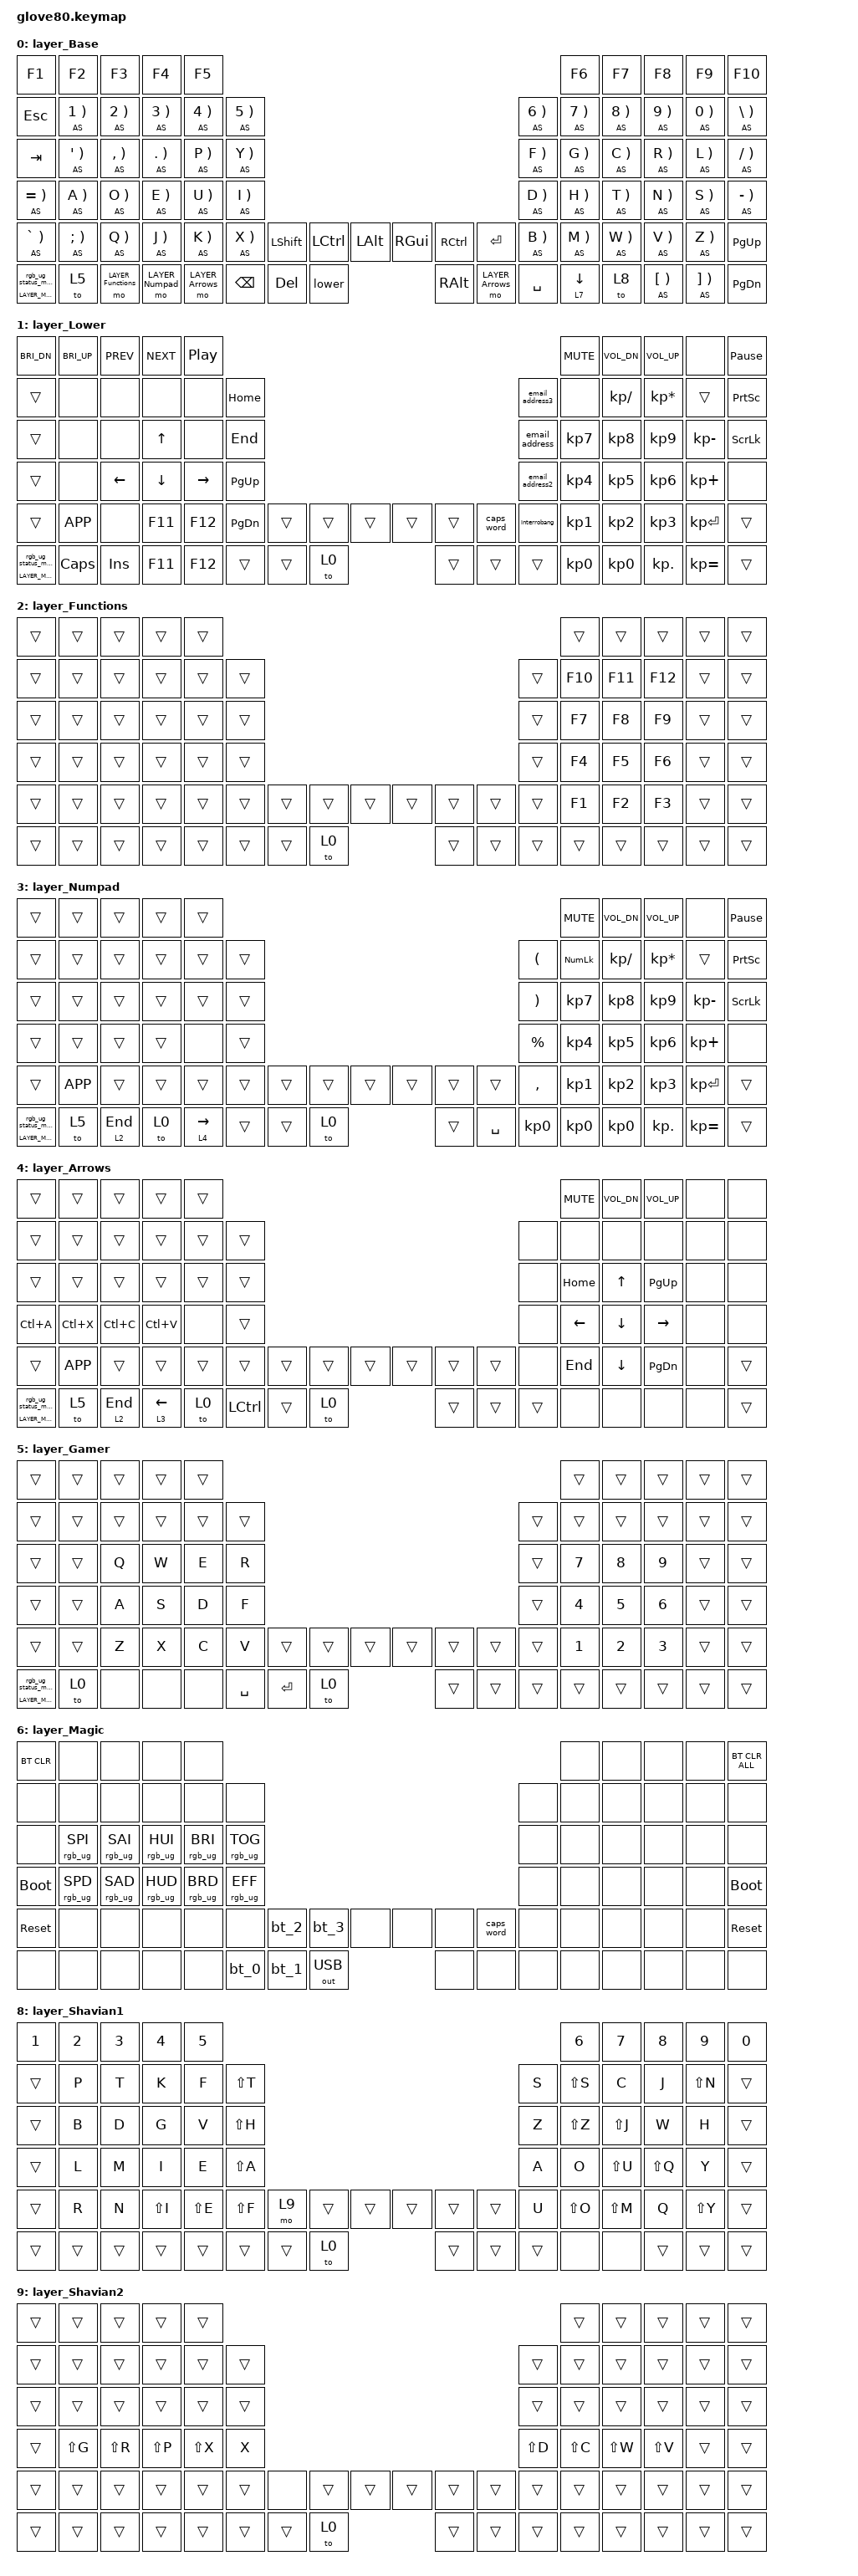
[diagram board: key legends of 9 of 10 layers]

/*
 * Copyright (c) 2020 The ZMK Contributors
 * Copyright (c) 2023 Innaworks Development Limited, trading as MoErgo
 *
 * SPDX-License-Identifier: MIT
 */


/* THIS FILE WAS GENERATED BY GLOVE80 LAYOUT EDITOR
 *
 * This file was generated automatically. You may or may not want to
 * edit it directly.
 */

#include <behaviors.dtsi>
/* Include all behaviour includes needed */
#include <dt-bindings/zmk/outputs.h>
#include <dt-bindings/zmk/keys.h>
#include <dt-bindings/zmk/bt.h>
#include <dt-bindings/zmk/rgb.h>
#include <dt-bindings/zmk/rgb_colors.h>

/* Automatically generated layer name #define */
#define LAYER_Base 0
#define LAYER_Lower 1
#define LAYER_Functions 2
#define LAYER_Numpad 3
#define LAYER_Arrows 4
#define LAYER_Gamer 5
#define LAYER_Magic 6
#define LAYER_OBS 7
#define LAYER_Shavian1 8
#define LAYER_Shavian2 9

/* To deal with the situation where there is no Lower layer, to keep &lower happy */
#ifndef LAYER_Lower
#define LAYER_Lower 0
#endif 

/* Custom Device-tree */
// KEY_REPEATING_TERM defines how much time you have left (milliseconds)
// after tapping a key to hold it again in order to make it auto-repeat.
#define KEY_REPEATING_TERM 800 // "tap then hold" for key auto-repeat

// TAPPING_TERM defines how long you need to hold (milliseconds)
// mod keys in order to send their modifiers to the computer
// (i.e. "register" them) for mod-click mouse usage (e.g. Ctrl-Click).
#define TAPPING_TERM 370 // TAPPING_TERM + ALLOW_CROSSOVER_AFTER
    
// AUTO_SHIFT_TERM defines how long you need to hold (milliseconds)
// a key in order to send its shifted version to the computer.
#define AUTO_SHIFT_TERM 300 // AUTO_SHIFT_TERM + ALLOW_CROSSOVER_AFTER

&mt {
    flavor = "hold-preferred";
    tapping-term-ms = <TAPPING_TERM>;
    quick-tap-ms = <KEY_REPEATING_TERM>;
};

&lt {
    flavor = "hold-preferred";
    tapping-term-ms = <TAPPING_TERM>;
    quick-tap-ms = <KEY_REPEATING_TERM>;
};


/ {
    underglow-layer {
        compatible  = "zmk,underglow-layer";

        lower {
            bindings = <
                ______ ______ ______ ______ ______                                                          ______ ______ ______ ______ ______
                ______ ______ ______ ______ ______ ______                                              BLUE ______ ______ ______ ______   PINK
                ______ ______ ______ ______ ______ ______                                              BLUE ______ ______ ______ ______   PINK
                ______ ______ ______ ______ ______ ______                                              BLUE ______ ______ ______ ______   PINK
                ______   PINK ______ YELLOW YELLOW ______ ______ ______ ______ ______  ______   PINK YELLOW ______ ______ ______ ______ ______
                ______   PINK ______ YELLOW YELLOW        ______  GREEN ______  ______ ______ ______        ______ ______ ______ ______ ______
                >;
            layer-id = <LAYER_Lower>;
        };
        arrows {
            bindings = <
                ______ ______ ______ ______ ______                                                          ______ ______ ______ ______ ______
                ______ ______ ______ ______ ______ ______                                            ______ ______ ______ ______ ______ ______
                ______ ______ ______ ______ ______ ______                                            ______   BLUE   BLUE   BLUE ______ ______
                  TEAL   BLUE   BLUE   BLUE ______ ______                                            ______   BLUE   BLUE   BLUE ______ ______
                ______ ______ ______ ______ ______ ______ ______ ______ ______  ______ ______ ______ ______   BLUE   BLUE   BLUE ______ ______
                ______ ______ ______ ______ ______          BLUE ______ ______  ______ ______ ______        ______ ______ ______ ______ ______
                >;
            layer-id = <LAYER_Arrows>;
        };
        numpad {
            bindings = <
                ______ ______ ______ ______ ______                                                          ______ ______ ______ ______ ______
                ______ ______ ______ ______ ______ ______                                            ______  GREEN  GREEN  GREEN ______ ______
                ______ ______ ______ ______ ______ ______                                            ______   TEAL   TEAL   TEAL  GREEN ______
                ______ ______ ______ ______ ______ ______                                              TEAL   TEAL   TEAL   TEAL  GREEN ______
                ______ ______ ______ ______ ______ ______ ______ ______ ______  ______ ______ ______   TEAL   TEAL   TEAL   TEAL  GREEN ______
                ______ ______ ______ ______ ______        ______ ______ ______  ______ ______   TEAL          TEAL   TEAL   TEAL  GREEN ______
                >;
            layer-id = <LAYER_Numpad>;
        };
        functions {
            bindings = <
                ______ ______ ______ ______ ______                                                          ______ ______ ______ ______ ______
                ______ ______ ______ ______ ______ ______                                            ______ YELLOW YELLOW YELLOW ______ ______
                ______ ______ ______ ______ ______ ______                                            ______ YELLOW YELLOW YELLOW ______ ______
                ______ ______ ______ ______ ______ ______                                            ______ YELLOW YELLOW YELLOW ______ ______
                ______ ______ ______ ______ ______ ______ ______ ______ ______  ______ ______ ______ ______ YELLOW YELLOW YELLOW ______ ______
                ______ ______ ______ ______ ______        ______ ______ ______  ______ ______ ______        ______ ______ ______ ______ ______
                >;
            layer-id = <LAYER_Functions>;
        };
        shavian1 {
            bindings = <
                  GOLD   GOLD   GOLD   GOLD   GOLD                                                            GOLD   GOLD   GOLD   GOLD   GOLD
                ______   GOLD   GOLD   GOLD   GOLD   GOLD                                              GOLD   GOLD   GOLD   GOLD   GOLD   GOLD
                ______   GOLD   GOLD   GOLD   GOLD   GOLD                                              GOLD   GOLD   GOLD   GOLD   GOLD ______
                ______   GOLD   GOLD   GOLD   GOLD   GOLD                                              GOLD   GOLD   GOLD   GOLD   GOLD ______
                ______   GOLD   GOLD   GOLD   GOLD   GOLD   GOLD ______ ______  ______ ______ ______   GOLD   GOLD   GOLD   GOLD   GOLD ______
                ______ ______ ______ ______ ______        ______ ______    RED  ______ ______ ______        ______ ______ ______ ______ ______
                >;
            layer-id = <LAYER_Shavian1>;
        };
        shavian2 {
            bindings = <
                ______ ______ ______ ______ ______                                                          ______ ______ ______ ______ ______
                ______ ______ ______ ______ ______ ______                                            ______ ______ ______ ______ ______ ______
                ______ ______ ______ ______ ______ ______                                            ______ ______ ______ ______ ______ ______
                ______   GOLD   GOLD   GOLD   GOLD   GOLD                                              GOLD   GOLD   GOLD   GOLD   GOLD ______
                ______ ______ ______ ______ ______ ______ ______ ______ ______  ______ ______ ______ ______ ______ ______ ______ ______ ______
                ______ ______ ______ ______ ______        ______ ______    RED  ______ ______ ______        ______ ______ ______ ______ ______
                >;
            layer-id = <LAYER_Shavian2>;
        };
        obs {
            bindings = <
                ______ ______ ______ ______ ______                                                          ______ ______ ______ ______ ______
                ______ ______ ______    RED ______  GREEN                                            ______ ______ ______ ______ ______ ______
                ______ ______ ORANGE   BLUE ______ ORANGE                                            ______ ______ ______ ______ ______ ______
                ______   GOLD   BLUE  GREEN   BLUE  GREEN                                            ______ ______ ______ ______ ______ ______
                ______ PURPLE   PINK   TEAL ______  GREEN ______ ______ ______  ______ ______ ______ ______ ______ ______ ______ ______ ______
                ______ ______  WHITE   TEAL ______        ______ ______ ______  ______ ______ ______        ______ ______ ______ ______ ______
                >;
            layer-id = <LAYER_OBS>;
        };
        gamer {
            bindings = <
                ______ ______ ______ ______ ______                                                          ______ ______ ______ ______ ______
                ______ ______ ______ ______ ______ ______                                            ______ ______ ______ ______ ______ ______
                ______ ______    RED    RED    RED ______                                            ______    RED    RED    RED ______ ______
                ______ ______    RED    RED    RED ______                                            ______    RED    RED    RED ______ ______
                ______ ______    RED    RED    RED ______ ______ ______ ______  ______ ______ ______ ______    RED    RED    RED ______ ______
                ______ ______ ______ ______ ______           RED    RED ______  ______ ______ ______        ______ ______ ______ ______ ______
                >;
            layer-id = <LAYER_Gamer>;
        };


    };
};


/* Glove80 system behavior & macros */
/ {
    behaviors {
        // For the "layer" key, it'd nice to be able to use it as either a shift or a toggle.
        // Configure it as a tap dance, so the first tap (or hold) is a &mo and the second tap is a &to
        lower: lower {
            compatible = "zmk,behavior-tap-dance";
            label = "LAYER_TAP_DANCE";
            #binding-cells = <0>;
            tapping-term-ms = <200>;
            bindings = <&mo LAYER_Lower>, <&to LAYER_Lower>;
        };
    };
};

/ {
    macros {
        rgb_ug_status_macro: rgb_ug_status_macro {
            label = "RGB_UG_STATUS";
            compatible = "zmk,behavior-macro";
            #binding-cells = <0>;
            bindings
                = <&rgb_ug RGB_STATUS>;
        };
    };
};


/ {
#ifdef BT_DISC_CMD
    behaviors {
        bt_0: bt_0 {
            compatible = "zmk,behavior-tap-dance";
            label = "BT_0";
            #binding-cells = <0>;
            tapping-term-ms = <200>;
            bindings = <&bt_select_0>, <&bt BT_DISC 0>;
        };
        bt_1: bt_1 {
            compatible = "zmk,behavior-tap-dance";
            label = "BT_1";
            #binding-cells = <0>;
            tapping-term-ms = <200>;
            bindings = <&bt_select_1>, <&bt BT_DISC 1>;
        };
        bt_2: bt_2 {
            compatible = "zmk,behavior-tap-dance";
            label = "BT_2";
            #binding-cells = <0>;
            tapping-term-ms = <200>;
            bindings = <&bt_select_2>, <&bt BT_DISC 2>;
        };
        bt_3: bt_3 {
            compatible = "zmk,behavior-tap-dance";
            label = "BT_3";
            #binding-cells = <0>;
            tapping-term-ms = <200>;
            bindings = <&bt_select_3>, <&bt BT_DISC 3>;
        };
    };
    macros {
        bt_select_0: bt_select_0 {
            label = "BT_SELECT_0";
            compatible = "zmk,behavior-macro";
            #binding-cells = <0>;
            bindings
                = <&out OUT_BLE>,
                  <&bt BT_SEL 0>;
        };
        bt_select_1: bt_select_1 {
            label = "BT_SELECT_1";
            compatible = "zmk,behavior-macro";
            #binding-cells = <0>;
            bindings
                = <&out OUT_BLE>,
                  <&bt BT_SEL 1>;
        };
        bt_select_2: bt_select_2 {
            label = "BT_SELECT_2";
            compatible = "zmk,behavior-macro";
            #binding-cells = <0>;
            bindings
                = <&out OUT_BLE>,
                  <&bt BT_SEL 2>;
        };
        bt_select_3: bt_select_3 {
            label = "BT_SELECT_3";
            compatible = "zmk,behavior-macro";
            #binding-cells = <0>;
            bindings
                = <&out OUT_BLE>,
                  <&bt BT_SEL 3>;
        };
    };
#else
    macros {
        bt_0: bt_0 {
            label = "BT_0";
            compatible = "zmk,behavior-macro";
            #binding-cells = <0>;
            bindings
                = <&out OUT_BLE>,
                  <&bt BT_SEL 0>;
        };
        bt_1: bt_1 {
            label = "BT_1";
            compatible = "zmk,behavior-macro";
            #binding-cells = <0>;
            bindings
                = <&out OUT_BLE>,
                  <&bt BT_SEL 1>;
        };
        bt_2: bt_2 {
            label = "BT_2";
            compatible = "zmk,behavior-macro";
            #binding-cells = <0>;
            bindings
                = <&out OUT_BLE>,
                  <&bt BT_SEL 2>;
        };
        bt_3: bt_3 {
            label = "BT_3";
            compatible = "zmk,behavior-macro";
            #binding-cells = <0>;
            bindings
                = <&out OUT_BLE>,
                  <&bt BT_SEL 3>;
        };
    };
#endif
};

/ {
    behaviors {
        magic: magic {
            compatible = "zmk,behavior-hold-tap";
            label = "MAGIC_HOLD_TAP";
            #binding-cells = <2>;
            flavor = "tap-preferred";
            tapping-term-ms = <200>;
            bindings = <&mo>, <&rgb_ug_status_macro>;
        };
    };
};

/* #define for key positions */
#define POS_LH_T1 52
#define POS_LH_T2 53
#define POS_LH_T3 54
#define POS_LH_T4 69
#define POS_LH_T5 70
#define POS_LH_T6 71
#define POS_LH_C1R2 15
#define POS_LH_C1R3 27
#define POS_LH_C1R4 39
#define POS_LH_C1R5 51
#define POS_LH_C2R1 4
#define POS_LH_C2R2 14
#define POS_LH_C2R3 26
#define POS_LH_C2R4 38
#define POS_LH_C2R5 50
#define POS_LH_C2R6 68
#define POS_LH_C3R1 3
#define POS_LH_C3R2 13
#define POS_LH_C3R3 25
#define POS_LH_C3R4 37
#define POS_LH_C3R5 49
#define POS_LH_C3R6 67
#define POS_LH_C4R1 2
#define POS_LH_C4R2 12
#define POS_LH_C4R3 24
#define POS_LH_C4R4 36
#define POS_LH_C4R5 48
#define POS_LH_C4R6 66
#define POS_LH_C5R1 1
#define POS_LH_C5R2 11
#define POS_LH_C5R3 23
#define POS_LH_C5R4 35
#define POS_LH_C5R5 47
#define POS_LH_C5R6 65
#define POS_LH_C6R1 0
#define POS_LH_C6R2 10
#define POS_LH_C6R3 22
#define POS_LH_C6R4 34
#define POS_LH_C6R5 46
#define POS_LH_C6R6 64
#define POS_RH_T1 57
#define POS_RH_T2 56
#define POS_RH_T3 55
#define POS_RH_T4 74
#define POS_RH_T5 73
#define POS_RH_T6 72
#define POS_RH_C1R2 16
#define POS_RH_C1R3 28
#define POS_RH_C1R4 40
#define POS_RH_C1R5 58
#define POS_RH_C2R1 5
#define POS_RH_C2R2 17
#define POS_RH_C2R3 29
#define POS_RH_C2R4 41
#define POS_RH_C2R5 59
#define POS_RH_C2R6 75
#define POS_RH_C3R1 6
#define POS_RH_C3R2 18
#define POS_RH_C3R3 30
#define POS_RH_C3R4 42
#define POS_RH_C3R5 60
#define POS_RH_C3R6 76
#define POS_RH_C4R1 7
#define POS_RH_C4R2 19
#define POS_RH_C4R3 31
#define POS_RH_C4R4 43
#define POS_RH_C4R5 61
#define POS_RH_C4R6 77
#define POS_RH_C5R1 8
#define POS_RH_C5R2 20
#define POS_RH_C5R3 32
#define POS_RH_C5R4 44
#define POS_RH_C5R5 62
#define POS_RH_C5R6 78
#define POS_RH_C6R1 9
#define POS_RH_C6R2 21
#define POS_RH_C6R3 33
#define POS_RH_C6R4 45
#define POS_RH_C6R5 63
#define POS_RH_C6R6 79

/* Custom Defined Behaviors */
/ {
behaviors {
  // Shifted version of a key on a long press
  #define AS(keycode) as LS(keycode) keycode
  as: auto_shift {
    compatible = "zmk,behavior-hold-tap";
    label = "AUTO_SHIFT";
    #binding-cells = <2>;
    tapping_term_ms = <AUTO_SHIFT_TERM>;
    quick_tap_ms = <KEY_REPEATING_TERM>;
    flavor = "tap-preferred";
    bindings = <&kp>, <&kp>;
  };
};

macros {
        arrow_layer: arrow_layer {
            label = "arrow_layer";
            compatible = "zmk,behavior-macro";
            #binding-cells = <0>;
            wait-ms = <0>;
            tap-ms = <0>;
            bindings
    = <&macro_press &mo LAYER_Arrows>
    //, <&macro_tap &rgb_ug RGB_COLOR_HSB(240,100,25)>
    //, <&macro_tap &rgb_ug RGB_ON>
    , <&macro_pause_for_release>
    , <&macro_release &mo LAYER_Arrows>;
    //, <&macro_tap &rgb_ug RGB_OFF>;
      };

 number_layer: number_layer {
            label = "number_layer";
            compatible = "zmk,behavior-macro";
            #binding-cells = <0>;
            wait-ms = <0>;
            tap-ms = <0>;
            bindings
    = <&macro_press &mo LAYER_Numpad>
    //, <&macro_tap &rgb_ug RGB_COLOR_HSB(120,100,25)>
    //, <&macro_tap &rgb_ug RGB_ON>
    , <&macro_pause_for_release>
    , <&macro_release &mo LAYER_Numpad>;
    //, <&macro_tap &rgb_ug RGB_OFF>;
      };

 function_layer: function_layer {
            label = "function_layer";
            compatible = "zmk,behavior-macro";
            #binding-cells = <0>;
            wait-ms = <0>;
            tap-ms = <0>;
            bindings
    = <&macro_press &mo LAYER_Functions>
    //, <&macro_tap &rgb_ug RGB_COLOR_HSB(60,100,25)>
    //, <&macro_tap &rgb_ug RGB_ON>
    , <&macro_pause_for_release>
    , <&macro_release &mo LAYER_Functions>;
    //, <&macro_tap &rgb_ug RGB_OFF>;
      };

 
 email_address: email_address {
             label = "email_address";
             compatible  = "zmk,behavior-macro";
            #binding-cells = <0>;
            wait-ms = <0>;
            tap-ms = <0>;
            bindings
    = <&macro_tap &kp AT_SIGN &kp F &kp R &kp E &kp S &kp E &kp N &kp I &kp U &kp S &kp M &kp E &kp D>;
      };
 email_address2: email_address2 {
             label = "email_address2";
             compatible  = "zmk,behavior-macro";
            #binding-cells = <0>;
            wait-ms = <0>;
            tap-ms = <0>;
            bindings
    = <&macro_tap &kp I &kp C &kp A &kp L &kp C &kp A &kp R &kp E &kp PERIOD &kp C &kp O &kp M>;
      };
 email_address3: email_address3 {
             label = "email_address3";
             compatible  = "zmk,behavior-macro";
            #binding-cells = <0>;
            wait-ms = <0>;
            tap-ms = <0>;
            bindings
    = <&macro_tap &kp D &kp A &kp N &kp I &kp E &kp L &kp PERIOD &kp C &kp A &kp L &kp L>;
      };
 interrobang: interrobang {
             label = "interrobang";
             compatible  = "zmk,behavior-macro";
            #binding-cells = <0>;
            wait-ms = <0>;
            tap-ms = <0>;
            bindings
    = <&macro_press &kp LALT>
    , <&macro_tap &kp KP_N8 &kp KP_N2 &kp KP_N5 &kp KP_N3>
    , <&macro_release &kp LALT>;
      };

};
};

/* Automatically generated macro definitions */
/ {
    macros {
    
    };
};

/* Automatically generated keymap */
/ {
    keymap {
        compatible = "zmk,keymap";


        layer_Base {
            bindings = <
               &kp F1      &kp F2           &kp F3         &kp F4        &kp F5                                                                                          &kp F6    &kp F7      &kp F8      &kp F9      &kp F10
              &kp ESC    &AS (N1)         &AS (N2)       &AS (N3)      &AS (N4)  &AS (N5)                                                                  &AS (N6)    &AS (N7)  &AS (N8)    &AS (N9)    &AS (N0)   &AS (BSLH)
              &kp TAB   &AS (SQT)      &AS (COMMA)      &AS (DOT)       &AS (P)   &AS (Y)                                                                   &AS (F)     &AS (G)   &AS (C)     &AS (R)     &AS (L)   &AS (FSLH)
          &AS (EQUAL)     &AS (A)          &AS (O)        &AS (E)       &AS (U)   &AS (I)                                                                   &AS (D)     &AS (H)   &AS (T)     &AS (N)     &AS (S)  &AS (MINUS)
          &AS (GRAVE)  &AS (SEMI)          &AS (Q)        &AS (J)       &AS (K)   &AS (X)  &kp LSHFT  &kp LCTRL  &kp LALT  &kp RGUI  &kp RCTRL    &kp RET   &AS (B)     &AS (M)   &AS (W)     &AS (V)     &AS (Z)    &kp PG_UP
 &magic LAYER_Magic 0       &to 5  &mo LAYER_Functions  &mo LAYER_Numpad  &mo LAYER_Arrows &kp BSPC    &kp DEL    &lower  &kp RALT   &mo LAYER_Arrows &kp SPACE        &lt 7 DOWN     &to 8  &AS (LBKT)  &AS (RBKT)    &kp PG_DN
            >;
        };

        layer_Lower {
            bindings = <
         &kp C_BRI_DN  &kp C_BRI_UP      &kp C_PREV      &kp C_NEXT         &kp C_PP                                                                                  &kp C_MUTE  &kp C_VOL_DN     &kp C_VOL_UP         &none  &kp PAUSE_BREAK
               &trans         &none           &none           &none            &none   &kp HOME                                                      &email_address3   &none  &kp KP_SLASH  &kp KP_MULTIPLY        &trans  &kp PRINTSCREEN
               &trans         &none           &none    &kp UP_ARROW            &none    &kp END                                                       &email_address   &kp KP_N7     &kp KP_N8        &kp KP_N9  &kp KP_MINUS   &kp SCROLLLOCK
               &trans         &none  &kp LEFT_ARROW  &kp DOWN_ARROW  &kp RIGHT_ARROW  &kp PG_UP                                                      &email_address2   &kp KP_N4     &kp KP_N5        &kp KP_N6   &kp KP_PLUS            &none
               &trans     &kp K_APP           &none         &kp F11          &kp F12  &kp PG_DN  &trans  &trans  &trans  &trans  &trans  &caps_word     &interrobang   &kp KP_N1     &kp KP_N2        &kp KP_N3  &kp KP_ENTER           &trans
 &magic LAYER_Magic 0      &kp CAPS         &kp INS         &kp F11          &kp F12             &trans  &trans   &to 0  &trans  &trans      &trans                    &kp KP_N0     &kp KP_N0       &kp KP_DOT  &kp KP_EQUAL           &trans
            >;
        };

        layer_Functions {
            bindings = <
 &trans  &trans  &trans  &trans  &trans                                                                   &trans   &trans   &trans  &trans  &trans
 &trans  &trans  &trans  &trans  &trans  &trans                                                  &trans  &kp F10  &kp F11  &kp F12  &trans  &trans
 &trans  &trans  &trans  &trans  &trans  &trans                                                  &trans   &kp F7   &kp F8   &kp F9  &trans  &trans
 &trans  &trans  &trans  &trans  &trans  &trans                                                  &trans   &kp F4   &kp F5   &kp F6  &trans  &trans
 &trans  &trans  &trans  &trans  &trans  &trans  &trans  &trans  &trans  &trans  &trans  &trans  &trans   &kp F1   &kp F2   &kp F3  &trans  &trans
 &trans  &trans  &trans  &trans  &trans          &trans  &trans   &to 0  &trans  &trans  &trans           &trans   &trans   &trans  &trans  &trans
            >;
        };

        layer_Numpad {
            bindings = <
               &trans     &trans     &trans  &trans       &trans                                                                                       &kp C_MUTE  &kp C_VOL_DN     &kp C_VOL_UP         &none  &kp PAUSE_BREAK
               &trans     &trans     &trans  &trans       &trans  &trans                                                         &kp LEFT_PARENTHESIS  &kp KP_NUM  &kp KP_SLASH  &kp KP_MULTIPLY        &trans  &kp PRINTSCREEN
               &trans     &trans     &trans  &trans       &trans  &trans                                                        &kp RIGHT_PARENTHESIS   &kp KP_N7     &kp KP_N8        &kp KP_N9  &kp KP_MINUS   &kp SCROLLLOCK
               &trans     &trans     &trans  &trans        &none  &trans                                                                  &kp PERCENT   &kp KP_N4     &kp KP_N5        &kp KP_N6   &kp KP_PLUS            &none
               &trans  &kp K_APP     &trans  &trans       &trans  &trans  &trans  &trans  &trans  &trans     &trans     &trans              &kp COMMA   &kp KP_N1     &kp KP_N2        &kp KP_N3  &kp KP_ENTER           &trans
 &magic LAYER_Magic 0      &to 5  &lt 2 END   &to 0  &lt 4 RIGHT          &trans  &trans   &to 0  &trans  &kp SPACE  &kp KP_N0                          &kp KP_N0     &kp KP_N0       &kp KP_DOT  &kp KP_EQUAL           &trans
            >;
        };

        layer_Arrows {
            bindings = <
               &trans     &trans     &trans      &trans  &trans                                                                     &kp C_MUTE  &kp C_VOL_DN  &kp C_VOL_UP   &none   &none
               &trans     &trans     &trans      &trans  &trans  &trans                                                      &none       &none         &none         &none   &none   &none
               &trans     &trans     &trans      &trans  &trans  &trans                                                      &none    &kp HOME        &kp UP     &kp PG_UP   &none   &none
               &kp LC(A)  &kp LC(X)  &kp LC(C)   &kp LC(V)   &none  &trans                                                      &none    &kp LEFT      &kp DOWN     &kp RIGHT   &none   &none
               &trans  &kp K_APP     &trans      &trans  &trans  &trans     &trans  &trans  &trans  &trans  &trans  &trans   &none     &kp END      &kp DOWN     &kp PG_DN   &none  &trans
 &magic LAYER_Magic 0      &to 5  &lt 2 END  &lt 3 LEFT   &to 0          &kp LCTRL  &trans   &to 0  &trans  &trans  &trans               &none         &none         &none   &none  &trans
            >;
        };

        layer_Gamer {
            bindings = <
               &trans  &trans  &trans  &trans  &trans                                                                      &trans  &trans  &trans  &trans  &trans
               &trans  &trans  &trans  &trans  &trans  &trans                                                      &trans  &trans  &trans  &trans  &trans  &trans
               &trans  &trans   &kp Q   &kp W   &kp E   &kp R                                                      &trans  &kp N7  &kp N8  &kp N9  &trans  &trans
               &trans  &trans   &kp A   &kp S   &kp D   &kp F                                                      &trans  &kp N4  &kp N5  &kp N6  &trans  &trans
               &trans  &trans   &kp Z   &kp X   &kp C   &kp V     &trans   &trans  &trans  &trans  &trans  &trans  &trans  &kp N1  &kp N2  &kp N3  &trans  &trans
 &magic LAYER_Magic 0   &to 0   &none   &none   &none          &kp SPACE  &kp RET   &to 0  &trans  &trans  &trans          &trans  &trans  &trans  &trans  &trans
            >;
        };

        layer_Magic {
            bindings = <
  &bt BT_CLR            &none            &none            &none            &none                                                                                      &none   &none   &none   &none  &bt BT_CLR_ALL
       &none            &none            &none            &none            &none            &none                                                             &none   &none   &none   &none   &none           &none
       &none  &rgb_ug RGB_SPI  &rgb_ug RGB_SAI  &rgb_ug RGB_HUI  &rgb_ug RGB_BRI  &rgb_ug RGB_TOG                                                             &none   &none   &none   &none   &none           &none
 &bootloader  &rgb_ug RGB_SPD  &rgb_ug RGB_SAD  &rgb_ug RGB_HUD  &rgb_ug RGB_BRD  &rgb_ug RGB_EFF                                                             &none   &none   &none   &none   &none     &bootloader
  &sys_reset            &none            &none            &none            &none            &none   &bt_2   &bt_3         &none   &none   &none  &caps_word   &none   &none   &none   &none   &none      &sys_reset
       &none            &none            &none            &none            &none                    &bt_0   &bt_1  &out OUT_USB   &none   &none       &none           &none   &none   &none   &none           &none
            >;
        };

        layer_OBS {
            bindings = <
                 &none                 &none                  &none               &none               &none                                                                                          &none   &none   &none   &none   &none
     &kp LC(LA(LS(D)))    &kp LC(LA(LS(N1)))     &kp LC(LA(LS(N2)))  &kp LC(LA(LS(N3)))  &kp LC(LA(LS(N4)))  &kp LC(LA(LS(N5)))                                                              &none   &none   &none   &none   &none   &none
     &kp LC(LA(LS(H)))   &kp LC(LA(LS(SQT)))  &kp LC(LA(LS(COMMA)))   &kp LC(LA(LS(F)))   &kp LC(LA(LS(P)))   &kp LC(LA(LS(Y)))                                                              &none   &none   &none   &none   &none   &none
 &kp LC(LA(LS(EQUAL)))     &kp LC(LA(LS(A)))      &kp LC(LA(LS(O)))   &kp LC(LA(LS(E)))   &kp LC(LA(LS(U)))   &kp LC(LA(LS(I)))                                                              &none   &none   &none   &none   &none   &none
     &kp LC(LA(LS(N)))  &kp LC(LA(LS(SEMI)))      &kp LC(LA(LS(Q)))   &kp LC(LA(LS(J)))   &kp LC(LA(LS(K)))   &kp LC(LA(LS(X)))  &kp LC(LA(LS(L)))   &none   &none   &none   &none   &none   &none   &none   &none   &none   &none   &none
  &magic LAYER_Magic 0     &kp LC(LA(LS(Z)))      &kp LC(LA(LS(V)))   &kp LC(LA(LS(W)))   &kp LC(LA(LS(M)))                      &kp LC(LA(LS(S)))   &none   &to 0   &none   &none   &none           &none   &none   &none   &none   &none
            >;
        };

        layer_Shavian1 {
            bindings = <
 &kp N1  &kp N2  &kp N3     &kp N4     &kp N5                                                                        &kp N6     &kp N7     &kp N8     &kp N9  &kp N0
 &trans   &kp P   &kp T      &kp K      &kp F  &kp LS(T)                                                   &kp S  &kp LS(S)      &kp C      &kp J  &kp LS(N)  &trans
 &trans   &kp B   &kp D      &kp G      &kp V  &kp LS(H)                                                   &kp Z  &kp LS(Z)  &kp LS(J)      &kp W      &kp H  &trans
 &trans   &kp L   &kp M      &kp I      &kp E  &kp LS(A)                                                   &kp A      &kp O  &kp LS(U)  &kp LS(Q)      &kp Y  &trans
 &trans   &kp R   &kp N  &kp LS(I)  &kp LS(E)  &kp LS(F)   &mo 9  &trans  &trans  &trans  &trans  &trans   &kp U  &kp LS(O)  &kp LS(M)      &kp Q  &kp LS(Y)  &trans
 &trans  &trans  &trans     &trans     &trans             &trans  &trans   &to 0  &trans  &trans  &trans              &none      &none     &trans     &trans  &trans
            >;
        };

        layer_Shavian2 {
            bindings = <
 &trans     &trans     &trans     &trans     &trans                                                                        &trans     &trans     &trans  &trans  &trans
 &trans     &trans     &trans     &trans     &trans  &trans                                                     &trans     &trans     &trans     &trans  &trans  &trans
 &trans     &trans     &trans     &trans     &trans  &trans                                                     &trans     &trans     &trans     &trans  &trans  &trans
 &trans  &kp LS(G)  &kp LS(R)  &kp LS(P)  &kp LS(X)   &kp X                                                  &kp LS(D)  &kp LS(C)  &kp LS(W)  &kp LS(V)  &trans  &trans
 &trans     &trans     &trans     &trans     &trans  &trans   &none  &trans  &trans  &trans  &trans  &trans     &trans     &trans     &trans     &trans  &trans  &trans
 &trans     &trans     &trans     &trans     &trans          &trans  &trans   &to 0  &trans  &trans  &trans                &trans     &trans     &trans  &trans  &trans
            >;
        };

    };
};
